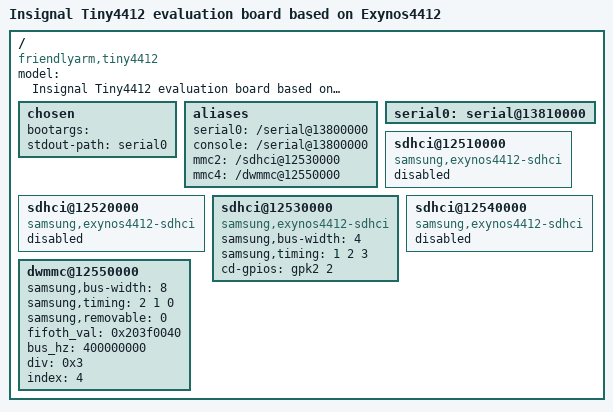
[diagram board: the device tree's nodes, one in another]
/*
 * Tiny4412 board device tree source
 *
 * Copyright (c) 2014 Samsung Electronics Co., Ltd.
 *		http://www.samsung.com
 *
 * SPDX-License-Identifier:	GPL-2.0+
 */

/dts-v1/;
#include "skeleton.dtsi"
//#include "exynos4210.dtsi"
#include "exynos4412.dtsi"

/ {
	model = "Insignal Tiny4412 evaluation board based on Exynos4412";
	compatible = "friendlyarm,tiny4412", "samsung,exynos4412", "samsung,exynos4";

	chosen {
		bootargs ="";
		/* 设置uart0作为终端 */
		stdout-path="serial0";
	};

	aliases {
		serial0 = "/serial@13800000";
		console = "/serial@13800000";
		mmc2 = "/sdhci@12530000";
		mmc4 = "/dwmmc@12550000";
	};

	serial0:serial@13810000 {
		status = "okay";
	};

	sdhci@12510000 {
		compatible = "samsung,exynos4412-sdhci";
		status = "disabled";
	};

	sdhci@12520000 {
		compatible = "samsung,exynos4412-sdhci";
		status = "disabled";
	};

	sdhci@12530000 {
		compatible = "samsung,exynos4412-sdhci";
		samsung,bus-width = <4>;
		samsung,timing = <1 2 3>;
		cd-gpios = <&gpk2 2 0>;
	};

	sdhci@12540000 {
		compatible = "samsung,exynos4412-sdhci";
		status = "disabled";
	};

	dwmmc@12550000 {
		samsung,bus-width = <8>;
		samsung,timing = <2 1 0>;
		samsung,removable = <0>;
		fifoth_val = <0x203f0040>;
		bus_hz = <400000000>;
		div = <0x3>;
		index = <4>;
	};
};
